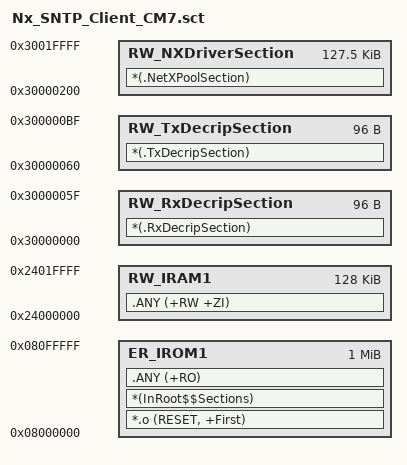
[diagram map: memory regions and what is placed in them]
; *************************************************************
; *** Scatter-Loading Description File generated by uVision ***
; *************************************************************

LR_IROM1 0x08000000 0x00100000  {    ; load region size_region
  ER_IROM1 0x08000000 0x00100000  {  ; load address = execution address
   *.o (RESET, +First)
   *(InRoot$$Sections)
   .ANY (+RO)
  }
  RW_IRAM1 0x24000000 0x00020000{  ; RW data
   .ANY (+RW +ZI)
  }
  
  RW_RxDecripSection 0x30000000 0x60  {
   *(.RxDecripSection)
  }

  RW_TxDecripSection 0x30000060 0x60  {
   *(.TxDecripSection)
  }

  RW_NXDriverSection 0x30000200 0x1FE00  {
  *(.NetXPoolSection)
  }
}
